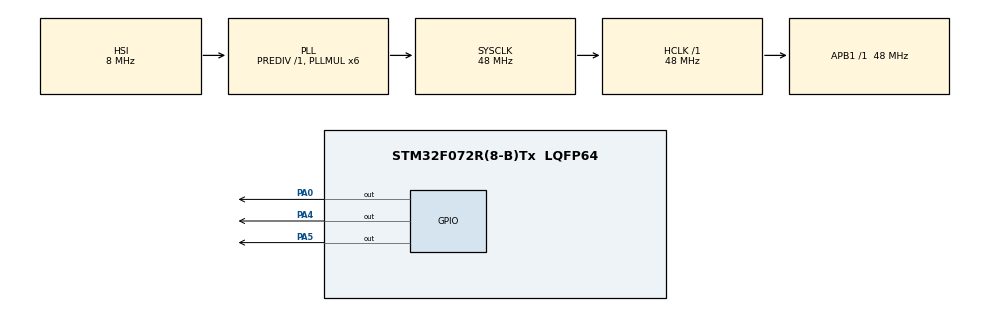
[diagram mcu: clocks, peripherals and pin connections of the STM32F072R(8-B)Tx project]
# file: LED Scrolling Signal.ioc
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Mcu.Family=STM32F0
RCC.PLLSourceVirtual=RCC_PLLSOURCE_HSE
RCC.SYSCLKSource=RCC_SYSCLKSOURCE_PLLCLK
ProjectManager.StackSize=0x400
PA13.Signal=SYS_SWDIO
ProjectManager.TargetToolchain=MDK-ARM V5
RCC.HCLKFreq_Value=48000000
RCC.AHBFreq_Value=48000000
PF0-OSC_IN.Mode=HSE-External-Oscillator
PA5.Signal=GPIO_Output
board=custom
RCC.PLLMUL=RCC_PLL_MUL6
PA14.Mode=Serial_Wire
PA13.Mode=Serial_Wire
Mcu.Name=STM32F072R(8-B)Tx
PA0.Signal=GPIO_Output
PA4.Signal=GPIO_Output
RCC.SYSCLKFreq_VALUE=48000000
Mcu.Package=LQFP64
PA14.Signal=SYS_SWCLK
ProjectManager.HeapSize=0x200
RCC.APB1TimFreq_Value=48000000
PF0-OSC_IN.Signal=RCC_OSC_IN
PF1-OSC_OUT.Mode=HSE-External-Oscillator
RCC.APB1Freq_Value=48000000
PF1-OSC_OUT.Signal=RCC_OSC_OUT

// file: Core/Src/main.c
/* USER CODE BEGIN Header */
/**
  ******************************************************************************
  * @file           : main.c
  * @brief          : Main program body
  ******************************************************************************
  * @attention
  *
  * <h2><center>&copy; Copyright (c) 2021 STMicroelectronics.
  * All rights reserved.</center></h2>
  *
  * This software component is licensed by ST under BSD 3-Clause license,
  * the "License"; You may not use this file except in compliance with the
  * License. You may obtain a copy of the License at:
  *                        opensource.org/licenses/BSD-3-Clause
  *
  ******************************************************************************
  */
/* USER CODE END Header */
#include "main.h"
#include "max_matrix_stm32.h"

void SystemClock_Config(void);
static void MX_GPIO_Init(void);

int main(void)
{

  /* MCU Configuration--------------------------------------------------------*/

  /* Reset of all peripherals, Initializes the Flash interface and the Systick. */
  HAL_Init();

  /* Configure the system clock */
  SystemClock_Config();

  /* Initialize all configured peripherals */
  MX_GPIO_Init();
  /* USER CODE BEGIN 2 */
	max_init(0x03); //display initialization
  /* USER CODE END 2 */

			write_char('A',4);
			write_char('B',3);
			write_char('C',2);
			write_char('D',1);
  /* Infinite loop */
  while (1)
  {

//			HAL_Delay(500);
//		scroll_char('p',100,left);
  }
}

void SystemClock_Config(void)
{
  RCC_OscInitTypeDef RCC_OscInitStruct = {0};
  RCC_ClkInitTypeDef RCC_ClkInitStruct = {0};

  /** Initializes the RCC Oscillators according to the specified parameters
  * in the RCC_OscInitTypeDef structure.
  */
  RCC_OscInitStruct.OscillatorType = RCC_OSCILLATORTYPE_HSI;
  RCC_OscInitStruct.HSIState = RCC_HSI_ON;
  RCC_OscInitStruct.HSICalibrationValue = RCC_HSICALIBRATION_DEFAULT;
  RCC_OscInitStruct.PLL.PLLState = RCC_PLL_ON;
  RCC_OscInitStruct.PLL.PLLSource = RCC_PLLSOURCE_HSI;
  RCC_OscInitStruct.PLL.PLLMUL = RCC_PLL_MUL6;
  RCC_OscInitStruct.PLL.PREDIV = RCC_PREDIV_DIV1;
  if (HAL_RCC_OscConfig(&RCC_OscInitStruct) != HAL_OK)
  {
    Error_Handler();
  }
  /** Initializes the CPU, AHB and APB buses clocks
  */
  RCC_ClkInitStruct.ClockType = RCC_CLOCKTYPE_HCLK|RCC_CLOCKTYPE_SYSCLK
                              |RCC_CLOCKTYPE_PCLK1;
  RCC_ClkInitStruct.SYSCLKSource = RCC_SYSCLKSOURCE_PLLCLK;
  RCC_ClkInitStruct.AHBCLKDivider = RCC_SYSCLK_DIV1;
  RCC_ClkInitStruct.APB1CLKDivider = RCC_HCLK_DIV1;

  if (HAL_RCC_ClockConfig(&RCC_ClkInitStruct, FLASH_LATENCY_1) != HAL_OK)
  {
    Error_Handler();
  }
}

static void MX_GPIO_Init(void)
{
  GPIO_InitTypeDef GPIO_InitStruct = {0};

  /* GPIO Ports Clock Enable */
  __HAL_RCC_GPIOF_CLK_ENABLE();
  __HAL_RCC_GPIOA_CLK_ENABLE();

  /*Configure GPIO pin Output Level */
  HAL_GPIO_WritePin(GPIOA, GPIO_PIN_0|GPIO_PIN_4|GPIO_PIN_5, GPIO_PIN_RESET);

  /*Configure GPIO pins : PA0 PA4 PA5 */
  GPIO_InitStruct.Pin = GPIO_PIN_0|GPIO_PIN_4|GPIO_PIN_5;
  GPIO_InitStruct.Mode = GPIO_MODE_OUTPUT_PP;
  GPIO_InitStruct.Pull = GPIO_NOPULL;
  GPIO_InitStruct.Speed = GPIO_SPEED_FREQ_LOW;
  HAL_GPIO_Init(GPIOA, &GPIO_InitStruct);

}

void Error_Handler(void)
{
  __disable_irq();
  while (1)
  {
  }
}

/************************ (C) COPYRIGHT STMicroelectronics *****END OF FILE****/
